VERSION ""

NS_ :

BS_:

BU_: ADTF
VAL_TABLE_ IEBM_State 15 "IEBM_STATE_ERROR" 2 "IEBM_STATE_EMERGENCY_BRAKING" 1 "IEBM_STATE_UPDATING" 0 "IEBM_STATE_STANDBY" ;
VAL_TABLE_ obst_types_to_be_considered 7 "THAS_ALL_OBSTACLES" 6 "THAS_DYNAMIC_AND_PEDESTRIANS" 5 "THAS_ONLY_PEDESTRIANS" 4 "THAS_ONLY_PEDESTRIANS" 3 "THAS_STATIC_AND_DYNAMIC," 2 "THAS_ONLY_DYNAMIC" 1 "THAS_ONLY_STATIC" 0 "default" ;

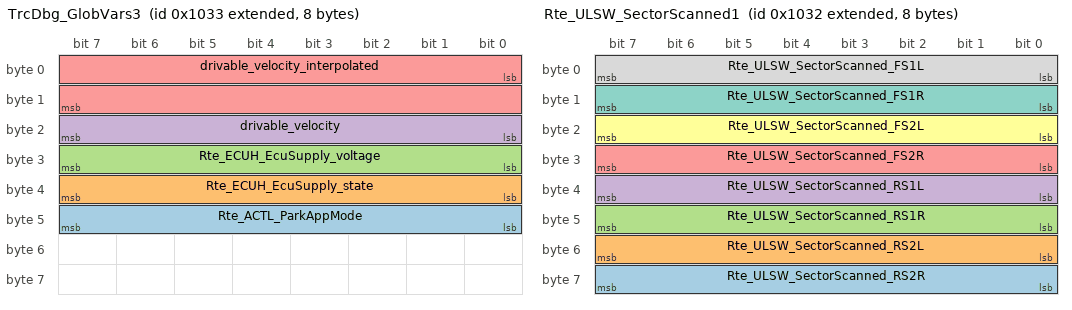
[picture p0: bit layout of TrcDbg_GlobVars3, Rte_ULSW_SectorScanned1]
BO_ 2147487795 TrcDbg_GlobVars3: 8 Vector__XXX
 SG_ Rte_ACTL_ParkAppMode : 40|8@1+ (1,0) [0|0] "" Vector__XXX
 SG_ Rte_ECUH_EcuSupply_state : 32|8@1+ (1,0) [0|0] "" Vector__XXX
 SG_ Rte_ECUH_EcuSupply_voltage : 24|8@1+ (1,0) [0|0] "" Vector__XXX
 SG_ drivable_velocity : 16|8@1+ (1,0) [0|0] "" Vector__XXX
 SG_ drivable_velocity_interpolated : 0|16@1- (1,0) [0|0] "" Vector__XXX

BO_ 2147487794 Rte_ULSW_SectorScanned1: 8 Vector__XXX
 SG_ Rte_ULSW_SectorScanned_RS2R : 56|8@1+ (1,0) [0|0] "" Vector__XXX
 SG_ Rte_ULSW_SectorScanned_RS2L : 48|8@1+ (1,0) [0|0] "" Vector__XXX
 SG_ Rte_ULSW_SectorScanned_RS1R : 40|8@1+ (1,0) [0|0] "" Vector__XXX
 SG_ Rte_ULSW_SectorScanned_RS1L : 32|8@1+ (1,0) [0|0] "" Vector__XXX
 SG_ Rte_ULSW_SectorScanned_FS2R : 24|8@1+ (1,0) [0|0] "" Vector__XXX
 SG_ Rte_ULSW_SectorScanned_FS2L : 16|8@1+ (1,0) [0|0] "" Vector__XXX
 SG_ Rte_ULSW_SectorScanned_FS1R : 8|8@1+ (1,0) [0|0] "" Vector__XXX
 SG_ Rte_ULSW_SectorScanned_FS1L : 0|8@1+ (1,0) [0|0] "" Vector__XXX

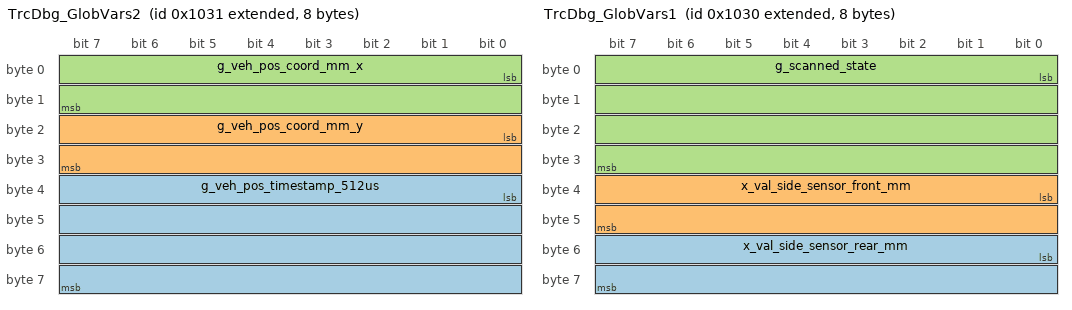
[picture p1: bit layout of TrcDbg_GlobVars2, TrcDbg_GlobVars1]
BO_ 2147487793 TrcDbg_GlobVars2: 8 Vector__XXX
 SG_ g_veh_pos_timestamp_512us : 32|32@1+ (1,0) [0|0] "" Vector__XXX
 SG_ g_veh_pos_coord_mm_y : 16|16@1- (1,0) [0|0] "" Vector__XXX
 SG_ g_veh_pos_coord_mm_x : 0|16@1- (1,0) [0|0] "" Vector__XXX

BO_ 2147487792 TrcDbg_GlobVars1: 8 ADTF
 SG_ x_val_side_sensor_rear_mm : 48|16@1- (1,0) [0|0] "" Vector__XXX
 SG_ x_val_side_sensor_front_mm : 32|16@1- (1,0) [0|0] "" Vector__XXX
 SG_ g_scanned_state : 0|32@1+ (1,0) [0|0] "" Vector__XXX

BA_DEF_  "BusType" STRING ;
BA_DEF_DEF_  "BusType" "CAN";
